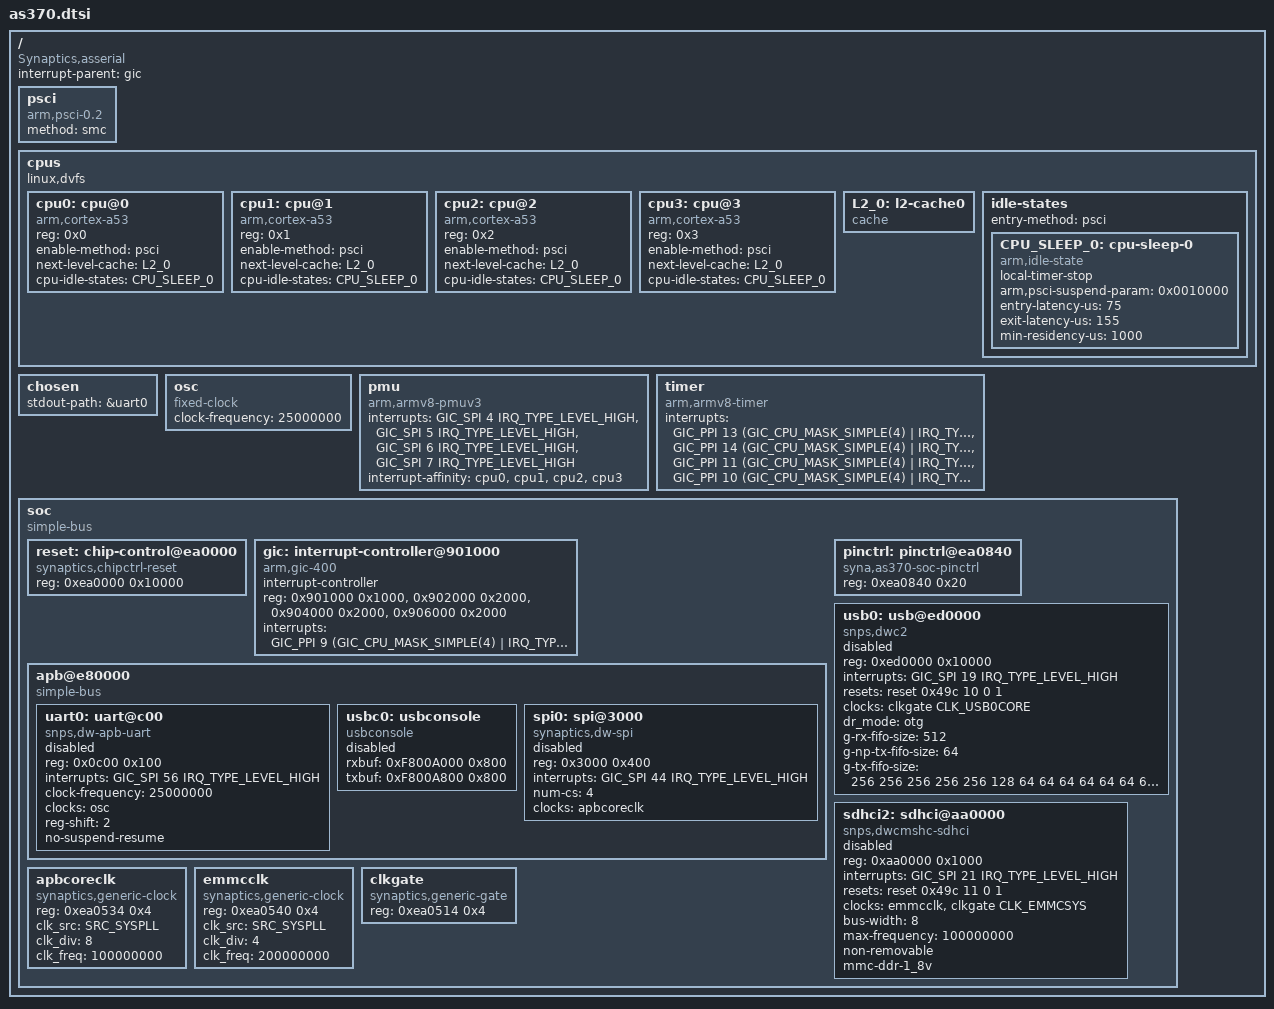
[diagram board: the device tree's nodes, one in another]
/* SPDX-License-Identifier: GPL-2.0+ */
/*
 * Copyright (C) 2019 Synaptics Incorporated
 *
 * Author:
 * Shaojun Feng <Shaojun.Feng@synaptics.com>
 * Cheng Lu <Cheng.Lu@synaptics.com>
 */


#include <dt-bindings/clock/as370.h>
#include <dt-bindings/interrupt-controller/arm-gic.h>

/ {
	compatible = "Synaptics,asserial";
	interrupt-parent = <&gic>;
	#address-cells = <2>;
	#size-cells = <2>;

	psci {
		compatible = "arm,psci-0.2";
		method = "smc";
	};

	cpus {
		#address-cells = <1>;
		#size-cells = <0>;
		linux,dvfs;

		cpu0: cpu@0 {
			device_type = "cpu";
			compatible = "arm,cortex-a53", "arm,armv8";
			reg = <0x0>;
			enable-method = "psci";
			next-level-cache = <&L2_0>;
			cpu-idle-states = <&CPU_SLEEP_0>;
		};

		cpu1: cpu@1 {
			device_type = "cpu";
			compatible = "arm,cortex-a53", "arm,armv8";
			reg = <0x1>;
			enable-method = "psci";
			next-level-cache = <&L2_0>;
			cpu-idle-states = <&CPU_SLEEP_0>;
		};

		cpu2: cpu@2 {
			device_type = "cpu";
			compatible = "arm,cortex-a53", "arm,armv8";
			reg = <0x2>;
			enable-method = "psci";
			next-level-cache = <&L2_0>;
			cpu-idle-states = <&CPU_SLEEP_0>;
		};

		cpu3: cpu@3 {
			device_type = "cpu";
			compatible = "arm,cortex-a53", "arm,armv8";
			reg = <0x3>;
			enable-method = "psci";
			next-level-cache = <&L2_0>;
			cpu-idle-states = <&CPU_SLEEP_0>;
		};

		L2_0: l2-cache0 {
			compatible = "cache";
		};

		idle-states {
			entry-method = "psci";
			CPU_SLEEP_0: cpu-sleep-0 {
				compatible = "arm,idle-state";
				local-timer-stop;
				arm,psci-suspend-param = <0x0010000>;
				entry-latency-us = <75>;
				exit-latency-us = <155>;
				min-residency-us = <1000>;
			};
		};

	};

	chosen {
		stdout-path = &uart0;
	};

	osc: osc {
		compatible = "fixed-clock";
		#clock-cells = <0>;
		clock-frequency = <25000000>;
	};

	pmu {
		compatible = "arm,armv8-pmuv3";
		interrupts = <GIC_SPI 4 IRQ_TYPE_LEVEL_HIGH>,
			     <GIC_SPI 5 IRQ_TYPE_LEVEL_HIGH>,
			     <GIC_SPI 6 IRQ_TYPE_LEVEL_HIGH>,
			     <GIC_SPI 7 IRQ_TYPE_LEVEL_HIGH>;
		interrupt-affinity = <&cpu0>,
				     <&cpu1>,
				     <&cpu2>,
				     <&cpu3>;
	};

	timer {
		compatible = "arm,armv8-timer";
		interrupts = <GIC_PPI 13 (GIC_CPU_MASK_SIMPLE(4) | IRQ_TYPE_LEVEL_LOW)>,
			     <GIC_PPI 14 (GIC_CPU_MASK_SIMPLE(4) | IRQ_TYPE_LEVEL_LOW)>,
			     <GIC_PPI 11 (GIC_CPU_MASK_SIMPLE(4) | IRQ_TYPE_LEVEL_LOW)>,
			     <GIC_PPI 10 (GIC_CPU_MASK_SIMPLE(4) | IRQ_TYPE_LEVEL_LOW)>;
	};

	soc {
		compatible = "simple-bus";
		#address-cells = <1>;
		#size-cells = <1>;
		ranges = <0 0 0xf7000000 0x1000000
			  0xe0000000 0 0xe0000000 0x10000000>;

		reset: chip-control@ea0000 {
			compatible = "synaptics,chipctrl-reset";
			reg = <0xea0000 0x10000>;
			#reset-cells = <4>;
                };

		gic: interrupt-controller@901000 {
			compatible = "arm,gic-400";
			#interrupt-cells = <3>;
			interrupt-controller;
			reg = <0x901000 0x1000>,
			      <0x902000 0x2000>,
			      <0x904000 0x2000>,
			      <0x906000 0x2000>;
			interrupts = <GIC_PPI 9 (GIC_CPU_MASK_SIMPLE(4) | IRQ_TYPE_LEVEL_HIGH)>;
		};

		apb@e80000 {
			compatible = "simple-bus";
			#address-cells = <1>;
			#size-cells = <1>;
			ranges = <0 0xe80000 0x10000>;
			/*
			interrupt-parent = <&aic>;
			*/

			uart0: uart@c00 {
				compatible = "snps,dw-apb-uart";
				reg = <0x0c00 0x100>;
				interrupts = <GIC_SPI 56 IRQ_TYPE_LEVEL_HIGH>;
				clock-frequency = <25000000>;
				clocks = <&osc>;
				reg-shift = <2>;
				no-suspend-resume;
				status = "disabled";
			};

			usbc0: usbconsole {
				compatible = "usbconsole";
				rxbuf = <0xF800A000 0x800>;
				txbuf = <0xF800A800 0x800>;
				status = "disabled";
                        };

			spi0: spi@3000 {
				compatible = "synaptics,dw-spi";
				#address-cells = <1>;
				#size-cells = <0>;
				reg = <0x3000 0x400>;
				interrupts = <GIC_SPI 44 IRQ_TYPE_LEVEL_HIGH>;
				num-cs = <4>;
				clocks = <&apbcoreclk>;
				status = "disabled";
			};

		};

		pinctrl: pinctrl@ea0840 {
			compatible = "syna,as370-soc-pinctrl";
			reg = <0xea0840 0x20>;
		};

		usb0: usb@ed0000 {
			compatible = "snps,dwc2";
			reg = <0xed0000 0x10000>;
			interrupts = <GIC_SPI 19 IRQ_TYPE_LEVEL_HIGH>;
			resets = <&reset 0x49c 10 0 1>;
			clocks = <&clkgate CLK_USB0CORE>;
			clock-names = "gate";
			dr_mode = "otg";
			g-rx-fifo-size = <512>;
			g-np-tx-fifo-size = <64>;
			g-tx-fifo-size = <256 256 256 256 256 128  64 64
						64  64  64  64  64  64  64>;
			status = "disabled";
		};

		sdhci2: sdhci@aa0000 {
			compatible = "snps,dwcmshc-sdhci";
			reg = <0xaa0000 0x1000>;
			interrupts = <GIC_SPI 21 IRQ_TYPE_LEVEL_HIGH>;
			resets = <&reset 0x49c 11 0 1>;
			clocks = <&emmcclk>, <&clkgate CLK_EMMCSYS>;
			clock-names = "core", "bus";
			bus-width = <8>;
			max-frequency = <100000000>;
			non-removable;
			mmc-ddr-1_8v;
			status = "disabled";
		};

		apbcoreclk: apbcoreclk {
			compatible = "synaptics,generic-clock";
			reg = <0xea0534 0x4>;
			#clock-cells = <0>;
			clk_src = <SRC_SYSPLL>;
			clk_div = <8>;
			clk_freq = <100000000>;
		};

		emmcclk: emmcclk {
			compatible = "synaptics,generic-clock";
			reg = <0xea0540 0x4>;
			#clock-cells = <0>;
			clk_src = <SRC_SYSPLL>;
			clk_div = <4>;
			clk_freq = <200000000>;
		};

		clkgate: clkgate {
			compatible = "synaptics,generic-gate";
			reg = <0xea0514 0x4>;
			#clock-cells = <1>;
		};

	};

};
